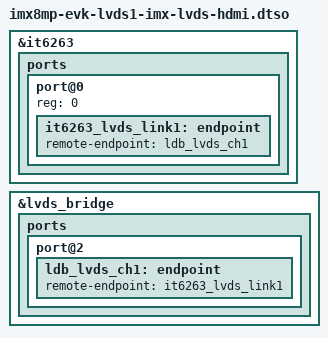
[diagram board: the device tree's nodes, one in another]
// SPDX-License-Identifier: (GPL-2.0+ OR MIT)
/*
 * Copyright 2024 NXP
 */

#include "imx8mp-evk-lvds1-imx-lvds-hdmi-common.dtsi"

&it6263 {
	ports {
		port@0 {
			reg = <0>;

			it6263_lvds_link1: endpoint {
				remote-endpoint = <&ldb_lvds_ch1>;
			};
		};
	};
};

&lvds_bridge {
	ports {
		port@2 {
			ldb_lvds_ch1: endpoint {
				remote-endpoint = <&it6263_lvds_link1>;
			};
		};
	};
};
